VERSION ""

NS_ :

BS_:

BU_: rr_ecu rl_ecu fr_ecu fl_ecu rear_ecu

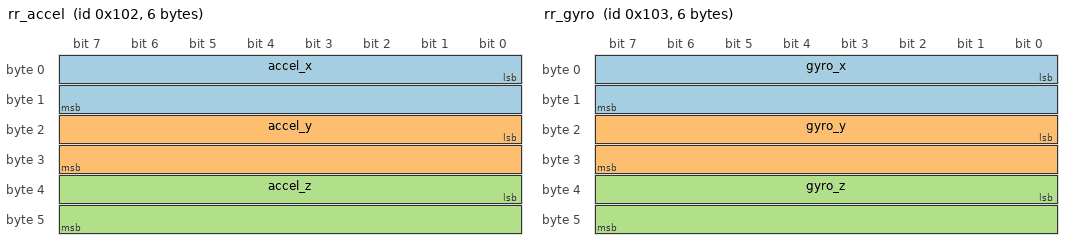
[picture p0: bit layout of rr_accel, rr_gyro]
BO_ 258 rr_accel: 6 rr_ecu
    SG_ accel_x : 0|16@1- (1,0) [-32768|32767] "g" Vector__XXX
    SG_ accel_y : 16|16@1- (1,0) [-32768|32767] "g" Vector__XXX
    SG_ accel_z : 32|16@1- (1,0) [-32768|32767] "g" Vector__XXX

BO_ 259 rr_gyro: 6 rr_ecu
    SG_ gyro_x : 0|16@1- (1,0) [-32768|32767] "dps" Vector__XXX
    SG_ gyro_y : 16|16@1- (1,0) [-32768|32767] "dps" Vector__XXX
    SG_ gyro_z : 32|16@1- (1,0) [-32768|32767] "dps" Vector__XXX

BO_ 260 rr_linpot: 2 rr_ecu
    SG_ lin_pot : 0|16@1+ (0.01,0) [0|655.35] "cm" Vector__XXX

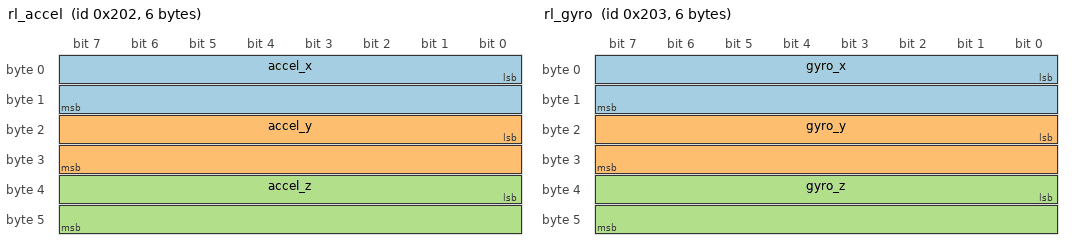
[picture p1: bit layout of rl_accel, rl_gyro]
BO_ 514 rl_accel: 6 rl_ecu
    SG_ accel_x : 0|16@1- (1,0) [-32768|32767] "g" Vector__XXX
    SG_ accel_y : 16|16@1- (1,0) [-32768|32767] "g" Vector__XXX
    SG_ accel_z : 32|16@1- (1,0) [-32768|32767] "g" Vector__XXX

BO_ 515 rl_gyro: 6 rl_ecu
    SG_ gyro_x : 0|16@1- (1,0) [-32768|32767] "dps" Vector__XXX
    SG_ gyro_y : 16|16@1- (1,0) [-32768|32767] "dps" Vector__XXX
    SG_ gyro_z : 32|16@1- (1,0) [-32768|32767] "dps" Vector__XXX

BO_ 516 rl_linpot: 2 rl_ecu
    SG_ lin_pot : 0|16@1+ (0.01,0) [0|655.35] "cm" Vector__XXX

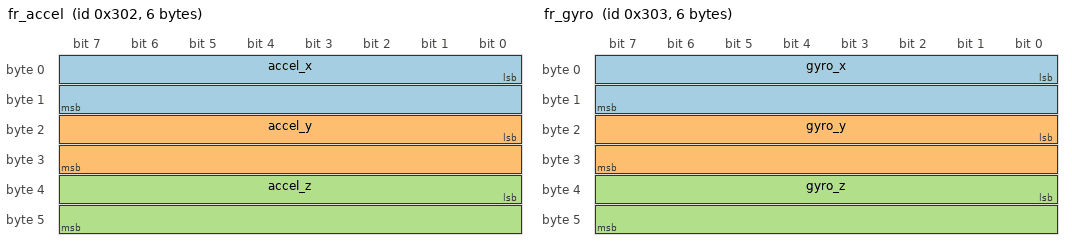
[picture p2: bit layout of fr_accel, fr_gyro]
BO_ 770 fr_accel: 6 fr_ecu
    SG_ accel_x : 0|16@1- (1,0) [-32768|32767] "g" Vector__XXX
    SG_ accel_y : 16|16@1- (1,0) [-32768|32767] "g" Vector__XXX
    SG_ accel_z : 32|16@1- (1,0) [-32768|32767] "g" Vector__XXX

BO_ 771 fr_gyro: 6 fr_ecu
    SG_ gyro_x : 0|16@1- (1,0) [-32768|32767] "dps" Vector__XXX
    SG_ gyro_y : 16|16@1- (1,0) [-32768|32767] "dps" Vector__XXX
    SG_ gyro_z : 32|16@1- (1,0) [-32768|32767] "dps" Vector__XXX

BO_ 772 fr_linpot: 2 fr_ecu
    SG_ lin_pot : 0|16@1+ (0.01,0) [0|655.35] "cm" Vector__XXX

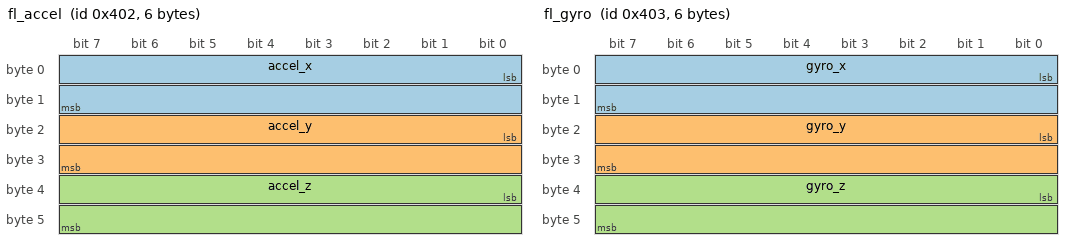
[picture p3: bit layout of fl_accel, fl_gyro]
BO_ 1026 fl_accel: 6 fl_ecu
    SG_ accel_x : 0|16@1- (1,0) [-32768|32767] "g" Vector__XXX
    SG_ accel_y : 16|16@1- (1,0) [-32768|32767] "g" Vector__XXX
    SG_ accel_z : 32|16@1- (1,0) [-32768|32767] "g" Vector__XXX

BO_ 1027 fl_gyro: 6 fl_ecu
    SG_ gyro_x : 0|16@1- (1,0) [-32768|32767] "dps" Vector__XXX
    SG_ gyro_y : 16|16@1- (1,0) [-32768|32767] "dps" Vector__XXX
    SG_ gyro_z : 32|16@1- (1,0) [-32768|32767] "dps" Vector__XXX

BO_ 1028 fl_linpot: 2 fl_ecu
    SG_ lin_pot : 0|16@1+ (0.01,0) [0|655.35] "cm" Vector__XXX

BO_ 1282 speedometer: 2 rear_ecu
    SG_ vehicle_speed : 0|16@1+ (1,0) [0|65535] "km/h" Vector__XXX

BO_ 1283 tachometer: 2 rear_ecu
    SG_ engine_rpm : 0|16@1+ (1,0) [0|65535] "rpm" Vector__XXX

BA_DEF_ BO_  "VFrameFormat" ENUM  "StandardCAN","ExtendedCAN","reserved","J1939PG";
BA_DEF_  "DatabaseVersion" STRING ;
BA_DEF_  "BusType" STRING ;
BA_DEF_  "ProtocolType" STRING ;
BA_DEF_  "DatabaseCompiler" STRING ;
BA_DEF_DEF_  "VFrameFormat" "J1939PG";
BA_DEF_DEF_  "DatabaseVersion" "";
BA_DEF_DEF_  "BusType" "";
BA_DEF_DEF_  "ProtocolType" "";
BA_DEF_DEF_  "DatabaseCompiler" "";
BA_ "BusType" "CAN";
BA_ "DatabaseCompiler" "UBC BAJA";
BA_ "DatabaseVersion" "1.0.0";
